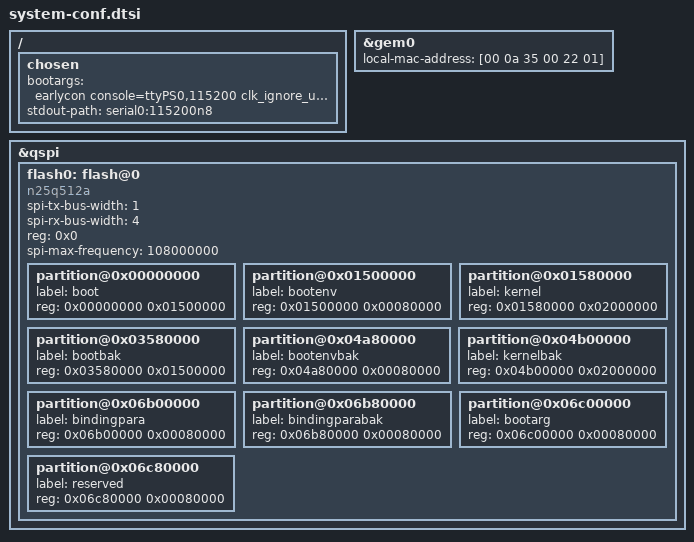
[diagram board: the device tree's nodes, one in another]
/*
 * CAUTION: This file is automatically generated by PetaLinux SDK.
 * DO NOT modify this file
 */


/ {
	chosen {
		bootargs = "earlycon console=ttyPS0,115200 clk_ignore_unused";
		stdout-path = "serial0:115200n8";
	};
};

&gem0 {
	local-mac-address = [00 0a 35 00 22 01];
};

&qspi {
	#address-cells = <1>;
	#size-cells = <0>;
	flash0: flash@0 {
		compatible = "n25q512a","micron,m25p80";
		spi-tx-bus-width=<1>;
		spi-rx-bus-width=<4>;
		reg = <0x0>;
		#address-cells = <1>;
		#size-cells = <1>;
		spi-max-frequency = <108000000>;
		/delete-node/ partition@qspi-fsbl-uboot;
		/delete-node/ partition@qspi-linux;
		/delete-node/ partition@qspi-device-tree;
		/delete-node/ partition@qspi-rootfs;
		/delete-node/ partition@qspi-bitstream;
		partition@0x00000000 {
			label = "boot";
			reg = <0x00000000 0x01500000>;
		};
		partition@0x01500000 {
			label = "bootenv";
			reg = <0x01500000 0x00080000>;
		};
		partition@0x01580000 {
			label = "kernel";
			reg = <0x01580000 0x02000000>;
		};
		partition@0x03580000 {
			label = "bootbak";
			reg = <0x03580000 0x01500000>;
		};
		partition@0x04a80000 {
			label = "bootenvbak";
			reg = <0x04a80000 0x00080000>;
		};
		partition@0x04b00000 {
			label = "kernelbak";
			reg = <0x04b00000 0x02000000>;
		};
		partition@0x06b00000 {
			label = "bindingpara";
			reg = <0x06b00000 0x00080000>;
		};
		partition@0x06b80000 {
			label = "bindingparabak";
			reg = <0x06b80000 0x00080000>;
		};
		partition@0x06c00000 {
			label = "bootarg";
			reg = <0x06c00000 0x00080000>;
		};
		partition@0x06c80000 {
			label = "reserved";
			reg = <0x06c80000 0x00080000>;
		};
	};
};

